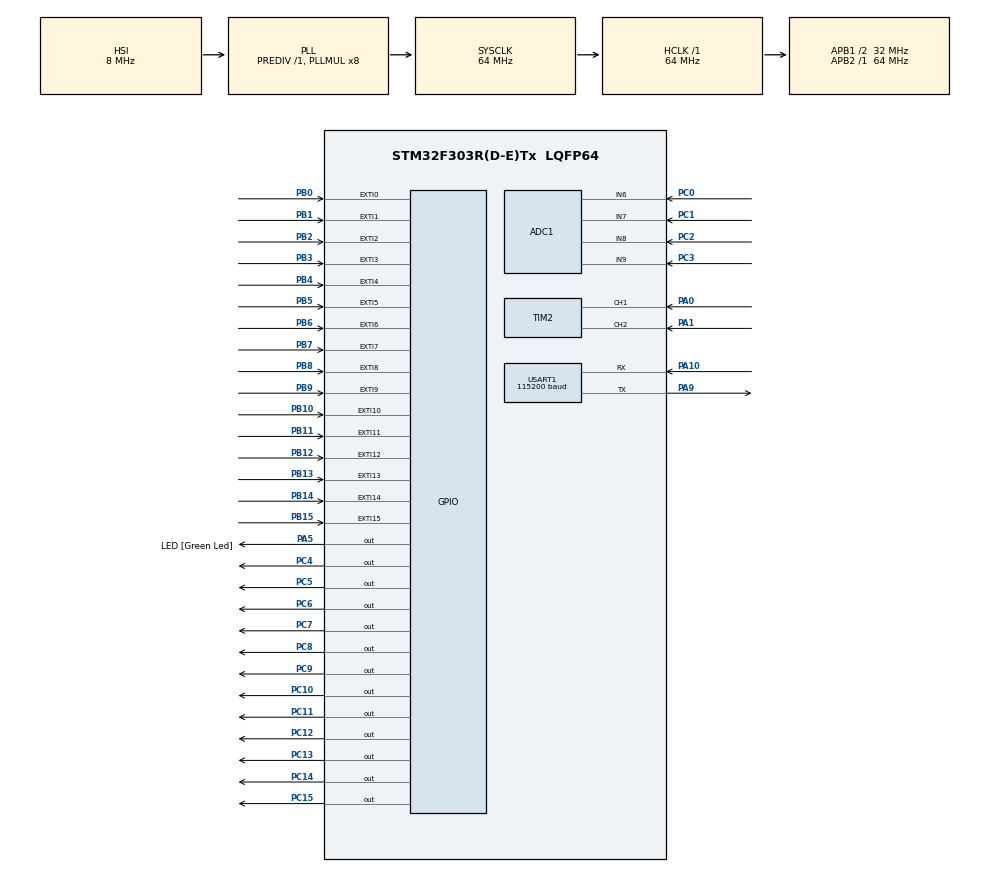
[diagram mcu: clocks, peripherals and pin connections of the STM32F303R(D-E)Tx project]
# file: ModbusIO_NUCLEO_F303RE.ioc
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ADC1.Channel-1\#ChannelRegularConversion=ADC_CHANNEL_6
ADC1.Channel-2\#ChannelRegularConversion=ADC_CHANNEL_7
ADC1.Channel-3\#ChannelRegularConversion=ADC_CHANNEL_8
ADC1.Channel-4\#ChannelRegularConversion=ADC_CHANNEL_9
ADC1.ContinuousConvMode=ENABLE
ADC1.DMAContinuousRequests=ENABLE
ADC1.EOCSelection=ADC_EOC_SEQ_CONV
ADC1.EnableInjectedConversion=DISABLE
ADC1.NbrOfConversion=4
ADC1.NbrOfConversionFlag=1
ADC1.Offset-1\#ChannelRegularConversion=0
ADC1.Offset-2\#ChannelRegularConversion=0
ADC1.Offset-3\#ChannelRegularConversion=0
ADC1.Offset-4\#ChannelRegularConversion=0
ADC1.OffsetNumber-1\#ChannelRegularConversion=ADC_OFFSET_NONE
ADC1.OffsetNumber-2\#ChannelRegularConversion=ADC_OFFSET_NONE
ADC1.OffsetNumber-3\#ChannelRegularConversion=ADC_OFFSET_NONE
ADC1.OffsetNumber-4\#ChannelRegularConversion=ADC_OFFSET_NONE
ADC1.Rank-1\#ChannelRegularConversion=1
ADC1.Rank-2\#ChannelRegularConversion=2
ADC1.Rank-3\#ChannelRegularConversion=3
ADC1.Rank-4\#ChannelRegularConversion=4
ADC1.SamplingTime-1\#ChannelRegularConversion=ADC_SAMPLETIME_61CYCLES_5
ADC1.SamplingTime-2\#ChannelRegularConversion=ADC_SAMPLETIME_61CYCLES_5
ADC1.SamplingTime-3\#ChannelRegularConversion=ADC_SAMPLETIME_61CYCLES_5
ADC1.SamplingTime-4\#ChannelRegularConversion=ADC_SAMPLETIME_61CYCLES_5
ADC1.master=1
Dma.ADC1.0.Direction=DMA_PERIPH_TO_MEMORY
Dma.ADC1.0.Instance=DMA1_Channel1
Dma.ADC1.0.MemDataAlignment=DMA_MDATAALIGN_HALFWORD
Dma.ADC1.0.MemInc=DMA_MINC_ENABLE
Dma.ADC1.0.Mode=DMA_CIRCULAR
Dma.ADC1.0.PeriphDataAlignment=DMA_PDATAALIGN_HALFWORD
Dma.ADC1.0.PeriphInc=DMA_PINC_DISABLE
Dma.ADC1.0.Priority=DMA_PRIORITY_LOW
Dma.Request0=ADC1
Mcu.Family=STM32F3
Mcu.Name=STM32F303R(D-E)Tx
Mcu.Package=LQFP64
NVIC.DMA1_Channel1_IRQn=true\:0\:0\:false\:false\:true\:false\:true\:true
NVIC.EXTI0_IRQn=true\:0\:0\:false\:false\:true\:true\:true\:true
NVIC.EXTI15_10_IRQn=true\:0\:0\:false\:false\:true\:true\:true\:true
NVIC.EXTI1_IRQn=true\:0\:0\:false\:false\:true\:true\:true\:true
NVIC.EXTI2_TSC_IRQn=true\:0\:0\:false\:false\:true\:true\:true\:true
NVIC.EXTI3_IRQn=true\:0\:0\:false\:false\:true\:true\:true\:true
NVIC.EXTI4_IRQn=true\:0\:0\:false\:false\:true\:true\:true\:true
NVIC.EXTI9_5_IRQn=true\:0\:0\:false\:false\:true\:true\:true\:true
NVIC.PriorityGroup=NVIC_PRIORITYGROUP_0
NVIC.USART1_IRQn=true\:0\:0\:false\:false\:true\:true\:true\:true
PA0.Signal=S_TIM2_CH1_ETR
PA1.Signal=S_TIM2_CH2
PA10.Mode=Asynchronous
PA10.Signal=USART1_RX
PA13.GPIO_Label=TMS
PA13.Signal=SYS_JTMS-SWDIO
PA14.GPIO_Label=TCK
PA14.Signal=SYS_JTCK-SWCLK
PA5.GPIO_Label=LED [Green Led]
PA5.GPIO_Mode=GPIO_MODE_OUTPUT_PP
PA5.GPIO_PuPd=GPIO_NOPULL
PA5.GPIO_Speed=GPIO_SPEED_FREQ_LOW
PA5.Signal=GPIO_Output
PA9.Mode=Asynchronous
PA9.Signal=USART1_TX
PB0.GPIO_ModeDefaultEXTI=GPIO_MODE_IT_FALLING
PB0.GPIO_PuPd=GPIO_PULLUP
PB0.Signal=GPXTI0
PB1.GPIO_ModeDefaultEXTI=GPIO_MODE_IT_FALLING
PB1.GPIO_PuPd=GPIO_PULLUP
PB1.Signal=GPXTI1
PB10.GPIO_ModeDefaultEXTI=GPIO_MODE_IT_FALLING
PB10.GPIO_PuPd=GPIO_PULLUP
PB10.Signal=GPXTI10
PB11.GPIO_ModeDefaultEXTI=GPIO_MODE_IT_FALLING
PB11.GPIO_PuPd=GPIO_PULLUP
PB11.Signal=GPXTI11
PB12.GPIO_ModeDefaultEXTI=GPIO_MODE_IT_FALLING
PB12.GPIO_PuPd=GPIO_PULLUP
PB12.Signal=GPXTI12
PB13.GPIO_ModeDefaultEXTI=GPIO_MODE_IT_FALLING
PB13.GPIO_PuPd=GPIO_PULLUP
PB13.Signal=GPXTI13
PB14.GPIO_ModeDefaultEXTI=GPIO_MODE_IT_FALLING
PB14.GPIO_PuPd=GPIO_PULLUP
PB14.Signal=GPXTI14
PB15.GPIO_ModeDefaultEXTI=GPIO_MODE_IT_FALLING
PB15.GPIO_PuPd=GPIO_PULLUP
PB15.Signal=GPXTI15
PB2.GPIO_ModeDefaultEXTI=GPIO_MODE_IT_FALLING
PB2.GPIO_PuPd=GPIO_PULLUP
PB2.Signal=GPXTI2
PB3.GPIO_ModeDefaultEXTI=GPIO_MODE_IT_FALLING
PB3.GPIO_PuPd=GPIO_PULLUP
PB3.Signal=GPXTI3
PB4.GPIO_ModeDefaultEXTI=GPIO_MODE_IT_FALLING
PB4.GPIO_PuPd=GPIO_PULLUP
PB4.Signal=GPXTI4
PB5.GPIO_ModeDefaultEXTI=GPIO_MODE_IT_FALLING
PB5.GPIO_PuPd=GPIO_PULLUP
PB5.Signal=GPXTI5
PB6.GPIO_ModeDefaultEXTI=GPIO_MODE_IT_FALLING
PB6.GPIO_PuPd=GPIO_PULLUP
PB6.Signal=GPXTI6
PB7.GPIO_ModeDefaultEXTI=GPIO_MODE_IT_FALLING
PB7.GPIO_PuPd=GPIO_PULLUP
PB7.Signal=GPXTI7
PB8.GPIO_ModeDefaultEXTI=GPIO_MODE_IT_FALLING
PB8.GPIO_PuPd=GPIO_PULLUP
PB8.Signal=GPXTI8
PB9.GPIO_ModeDefaultEXTI=GPIO_MODE_IT_FALLING
PB9.GPIO_PuPd=GPIO_PULLUP
PB9.Signal=GPXTI9
PC0.Signal=ADCx_IN6
PC1.Signal=ADCx_IN7
PC10.Signal=GPIO_Output
PC11.Signal=GPIO_Output
PC12.Signal=GPIO_Output
PC13.Signal=GPIO_Output
PC14-OSC32_IN.Signal=GPIO_Output
PC15-OSC32_OUT.Signal=GPIO_Output
PC2.Signal=ADCx_IN8
PC3.Signal=ADCx_IN9
PC4.Signal=GPIO_Output
PC5.Signal=GPIO_Output
PC6.Signal=GPIO_Output
PC7.Signal=GPIO_Output
PC8.Signal=GPIO_Output
PC9.Signal=GPIO_Output
PF0-OSC_IN.Signal=RCC_OSC_IN
PF1-OSC_OUT.Signal=RCC_OSC_OUT
ProjectManager.HeapSize=0x200
ProjectManager.StackSize=0x400
ProjectManager.TargetToolchain=STM32CubeIDE
RCC.ADC12PRES=RCC_ADC12PLLCLK_DIV64
RCC.AHBFreq_Value=64000000
RCC.APB1CLKDivider=RCC_HCLK_DIV2
RCC.APB1Freq_Value=32000000
RCC.APB1TimFreq_Value=64000000
RCC.APB2Freq_Value=64000000
RCC.APB2TimFreq_Value=64000000
RCC.CortexFreq_Value=64000000
RCC.HCLKFreq_Value=64000000
RCC.HSE_VALUE=8000000
RCC.HSI_VALUE=8000000
RCC.LSE_VALUE=32768
RCC.PLLM=8
RCC.PLLMUL=RCC_PLL_MUL8
RCC.PLLN=336
RCC.PLLP=RCC_PLLP_DIV4
RCC.PLLQ=7
RCC.RCC_PLLsource_Clock_Source_FROM_HSE=RCC_HSE_PREDIV_DIV2
RCC.SYSCLKFreq_VALUE=64000000
RCC.SYSCLKSourceVirtual=RCC_SYSCLKSOURCE_PLLCLK
RCC.USBFreq_Value=64000000
SH.ADCx_IN6.0=ADC1_IN6,IN6-Single-Ended
SH.ADCx_IN7.0=ADC1_IN7,IN7-Single-Ended
SH.ADCx_IN8.0=ADC1_IN8,IN8-Single-Ended
SH.ADCx_IN9.0=ADC1_IN9,IN9-Single-Ended
SH.S_TIM2_CH1_ETR.0=TIM2_CH1,Encoder_Interface
SH.S_TIM2_CH2.0=TIM2_CH2,Encoder_Interface
USART1.BaudRate=115200
USART1.VirtualMode-Asynchronous=VM_ASYNC
board=NUCLEO-F303RE

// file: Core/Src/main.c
/* USER CODE BEGIN Header */
/**
  ******************************************************************************
  * @file           : main.c
  * @brief          : Main program body
  ******************************************************************************
  * @attention
  *
  * Copyright (c) 2024 STMicroelectronics.
  * All rights reserved.
  *
  * This software is licensed under terms that can be found in the LICENSE file
  * in the root directory of this software component.
  * If no LICENSE file comes with this software, it is provided AS-IS.
  *
  ******************************************************************************
  */
/* USER CODE END Header */
#include "main.h"

ADC_HandleTypeDef hadc1;
DMA_HandleTypeDef hdma_adc1;

TIM_HandleTypeDef htim2;

UART_HandleTypeDef huart1;

void SystemClock_Config(void);
static void MX_GPIO_Init(void);
static void MX_DMA_Init(void);
static void MX_ADC1_Init(void);
static void MX_TIM2_Init(void);
static void MX_USART1_UART_Init(void);

/* USER CODE BEGIN 0 */
void StartPeripherals(void);
void MainLoop(void);
/* USER CODE END 0 */

int main(void)
{

  /* MCU Configuration--------------------------------------------------------*/

  /* Reset of all peripherals, Initializes the Flash interface and the Systick. */
  HAL_Init();

  /* Configure the system clock */
  SystemClock_Config();

  /* Initialize all configured peripherals */
  MX_GPIO_Init();
  MX_DMA_Init();
  MX_ADC1_Init();
  MX_TIM2_Init();
  MX_USART1_UART_Init();
  /* USER CODE BEGIN 2 */
  StartPeripherals();
  /* USER CODE END 2 */

  /* Infinite loop */
  /* USER CODE BEGIN WHILE */
  MainLoop();
    /* USER CODE END WHILE */

}

void SystemClock_Config(void)
{
  RCC_OscInitTypeDef RCC_OscInitStruct = {0};
  RCC_ClkInitTypeDef RCC_ClkInitStruct = {0};
  RCC_PeriphCLKInitTypeDef PeriphClkInit = {0};

  /** Initializes the RCC Oscillators according to the specified parameters
  * in the RCC_OscInitTypeDef structure.
  */
  RCC_OscInitStruct.OscillatorType = RCC_OSCILLATORTYPE_HSI;
  RCC_OscInitStruct.HSIState = RCC_HSI_ON;
  RCC_OscInitStruct.HSICalibrationValue = RCC_HSICALIBRATION_DEFAULT;
  RCC_OscInitStruct.PLL.PLLState = RCC_PLL_ON;
  RCC_OscInitStruct.PLL.PLLSource = RCC_PLLSOURCE_HSI;
  RCC_OscInitStruct.PLL.PLLMUL = RCC_PLL_MUL8;
  RCC_OscInitStruct.PLL.PREDIV = RCC_PREDIV_DIV1;
  if (HAL_RCC_OscConfig(&RCC_OscInitStruct) != HAL_OK)
  {
    Error_Handler();
  }

  /** Initializes the CPU, AHB and APB buses clocks
  */
  RCC_ClkInitStruct.ClockType = RCC_CLOCKTYPE_HCLK|RCC_CLOCKTYPE_SYSCLK
                              |RCC_CLOCKTYPE_PCLK1|RCC_CLOCKTYPE_PCLK2;
  RCC_ClkInitStruct.SYSCLKSource = RCC_SYSCLKSOURCE_PLLCLK;
  RCC_ClkInitStruct.AHBCLKDivider = RCC_SYSCLK_DIV1;
  RCC_ClkInitStruct.APB1CLKDivider = RCC_HCLK_DIV2;
  RCC_ClkInitStruct.APB2CLKDivider = RCC_HCLK_DIV1;

  if (HAL_RCC_ClockConfig(&RCC_ClkInitStruct, FLASH_LATENCY_2) != HAL_OK)
  {
    Error_Handler();
  }
  PeriphClkInit.PeriphClockSelection = RCC_PERIPHCLK_USART1|RCC_PERIPHCLK_ADC12
                              |RCC_PERIPHCLK_TIM2;
  PeriphClkInit.Usart1ClockSelection = RCC_USART1CLKSOURCE_PCLK2;
  PeriphClkInit.Adc12ClockSelection = RCC_ADC12PLLCLK_DIV64;
  PeriphClkInit.Tim2ClockSelection = RCC_TIM2CLK_HCLK;
  if (HAL_RCCEx_PeriphCLKConfig(&PeriphClkInit) != HAL_OK)
  {
    Error_Handler();
  }
}

static void MX_ADC1_Init(void)
{

  ADC_MultiModeTypeDef multimode = {0};
  ADC_ChannelConfTypeDef sConfig = {0};

  /** Common config
  */
  hadc1.Instance = ADC1;
  hadc1.Init.ClockPrescaler = ADC_CLOCK_ASYNC_DIV1;
  hadc1.Init.Resolution = ADC_RESOLUTION_12B;
  hadc1.Init.ScanConvMode = ADC_SCAN_ENABLE;
  hadc1.Init.ContinuousConvMode = ENABLE;
  hadc1.Init.DiscontinuousConvMode = DISABLE;
  hadc1.Init.ExternalTrigConvEdge = ADC_EXTERNALTRIGCONVEDGE_NONE;
  hadc1.Init.ExternalTrigConv = ADC_SOFTWARE_START;
  hadc1.Init.DataAlign = ADC_DATAALIGN_RIGHT;
  hadc1.Init.NbrOfConversion = 4;
  hadc1.Init.DMAContinuousRequests = ENABLE;
  hadc1.Init.EOCSelection = ADC_EOC_SEQ_CONV;
  hadc1.Init.LowPowerAutoWait = DISABLE;
  hadc1.Init.Overrun = ADC_OVR_DATA_OVERWRITTEN;
  if (HAL_ADC_Init(&hadc1) != HAL_OK)
  {
    Error_Handler();
  }

  /** Configure the ADC multi-mode
  */
  multimode.Mode = ADC_MODE_INDEPENDENT;
  if (HAL_ADCEx_MultiModeConfigChannel(&hadc1, &multimode) != HAL_OK)
  {
    Error_Handler();
  }

  /** Configure Regular Channel
  */
  sConfig.Channel = ADC_CHANNEL_6;
  sConfig.Rank = ADC_REGULAR_RANK_1;
  sConfig.SingleDiff = ADC_SINGLE_ENDED;
  sConfig.SamplingTime = ADC_SAMPLETIME_61CYCLES_5;
  sConfig.OffsetNumber = ADC_OFFSET_NONE;
  sConfig.Offset = 0;
  if (HAL_ADC_ConfigChannel(&hadc1, &sConfig) != HAL_OK)
  {
    Error_Handler();
  }

  /** Configure Regular Channel
  */
  sConfig.Channel = ADC_CHANNEL_7;
  sConfig.Rank = ADC_REGULAR_RANK_2;
  if (HAL_ADC_ConfigChannel(&hadc1, &sConfig) != HAL_OK)
  {
    Error_Handler();
  }

  /** Configure Regular Channel
  */
  sConfig.Channel = ADC_CHANNEL_8;
  sConfig.Rank = ADC_REGULAR_RANK_3;
  if (HAL_ADC_ConfigChannel(&hadc1, &sConfig) != HAL_OK)
  {
    Error_Handler();
  }

  /** Configure Regular Channel
  */
  sConfig.Channel = ADC_CHANNEL_9;
  sConfig.Rank = ADC_REGULAR_RANK_4;
  if (HAL_ADC_ConfigChannel(&hadc1, &sConfig) != HAL_OK)
  {
    Error_Handler();
  }

}

static void MX_TIM2_Init(void)
{

  TIM_Encoder_InitTypeDef sConfig = {0};
  TIM_MasterConfigTypeDef sMasterConfig = {0};

  htim2.Instance = TIM2;
  htim2.Init.Prescaler = 0;
  htim2.Init.CounterMode = TIM_COUNTERMODE_UP;
  htim2.Init.Period = 4294967295;
  htim2.Init.ClockDivision = TIM_CLOCKDIVISION_DIV1;
  htim2.Init.AutoReloadPreload = TIM_AUTORELOAD_PRELOAD_DISABLE;
  sConfig.EncoderMode = TIM_ENCODERMODE_TI1;
  sConfig.IC1Polarity = TIM_ICPOLARITY_RISING;
  sConfig.IC1Selection = TIM_ICSELECTION_DIRECTTI;
  sConfig.IC1Prescaler = TIM_ICPSC_DIV1;
  sConfig.IC1Filter = 0;
  sConfig.IC2Polarity = TIM_ICPOLARITY_RISING;
  sConfig.IC2Selection = TIM_ICSELECTION_DIRECTTI;
  sConfig.IC2Prescaler = TIM_ICPSC_DIV1;
  sConfig.IC2Filter = 0;
  if (HAL_TIM_Encoder_Init(&htim2, &sConfig) != HAL_OK)
  {
    Error_Handler();
  }
  sMasterConfig.MasterOutputTrigger = TIM_TRGO_RESET;
  sMasterConfig.MasterSlaveMode = TIM_MASTERSLAVEMODE_DISABLE;
  if (HAL_TIMEx_MasterConfigSynchronization(&htim2, &sMasterConfig) != HAL_OK)
  {
    Error_Handler();
  }

}

static void MX_USART1_UART_Init(void)
{

  huart1.Instance = USART1;
  huart1.Init.BaudRate = 115200;
  huart1.Init.WordLength = UART_WORDLENGTH_8B;
  huart1.Init.StopBits = UART_STOPBITS_1;
  huart1.Init.Parity = UART_PARITY_NONE;
  huart1.Init.Mode = UART_MODE_TX_RX;
  huart1.Init.HwFlowCtl = UART_HWCONTROL_NONE;
  huart1.Init.OverSampling = UART_OVERSAMPLING_16;
  huart1.Init.OneBitSampling = UART_ONE_BIT_SAMPLE_DISABLE;
  huart1.AdvancedInit.AdvFeatureInit = UART_ADVFEATURE_NO_INIT;
  if (HAL_UART_Init(&huart1) != HAL_OK)
  {
    Error_Handler();
  }

}

static void MX_DMA_Init(void)
{

  /* DMA controller clock enable */
  __HAL_RCC_DMA1_CLK_ENABLE();

  /* DMA interrupt init */
  /* DMA1_Channel1_IRQn interrupt configuration */
  HAL_NVIC_SetPriority(DMA1_Channel1_IRQn, 0, 0);
  HAL_NVIC_EnableIRQ(DMA1_Channel1_IRQn);

}

static void MX_GPIO_Init(void)
{
  GPIO_InitTypeDef GPIO_InitStruct = {0};

  /* GPIO Ports Clock Enable */
  __HAL_RCC_GPIOF_CLK_ENABLE();
  __HAL_RCC_GPIOC_CLK_ENABLE();
  __HAL_RCC_GPIOA_CLK_ENABLE();
  __HAL_RCC_GPIOB_CLK_ENABLE();

  /*Configure GPIO pin Output Level */
  HAL_GPIO_WritePin(LED_GPIO_Port, LED_Pin, GPIO_PIN_RESET);

  /*Configure GPIO pin Output Level */
  HAL_GPIO_WritePin(GPIOC, GPIO_PIN_13|GPIO_PIN_14|GPIO_PIN_15|GPIO_PIN_4
                          |GPIO_PIN_5|GPIO_PIN_6|GPIO_PIN_7|GPIO_PIN_8
                          |GPIO_PIN_9|GPIO_PIN_10|GPIO_PIN_11|GPIO_PIN_12, GPIO_PIN_RESET);

  /*Configure GPIO pin : LED_Pin */
  GPIO_InitStruct.Pin = LED_Pin;
  GPIO_InitStruct.Mode = GPIO_MODE_OUTPUT_PP;
  GPIO_InitStruct.Pull = GPIO_NOPULL;
  GPIO_InitStruct.Speed = GPIO_SPEED_FREQ_LOW;
  HAL_GPIO_Init(LED_GPIO_Port, &GPIO_InitStruct);

  /*Configure GPIO pins : PC13 PC14 PC15 PC4
                           PC5 PC6 PC7 PC8
                           PC9 PC10 PC11 PC12 */
  GPIO_InitStruct.Pin = GPIO_PIN_13|GPIO_PIN_14|GPIO_PIN_15|GPIO_PIN_4
                          |GPIO_PIN_5|GPIO_PIN_6|GPIO_PIN_7|GPIO_PIN_8
                          |GPIO_PIN_9|GPIO_PIN_10|GPIO_PIN_11|GPIO_PIN_12;
  GPIO_InitStruct.Mode = GPIO_MODE_OUTPUT_PP;
  GPIO_InitStruct.Pull = GPIO_NOPULL;
  GPIO_InitStruct.Speed = GPIO_SPEED_FREQ_LOW;
  HAL_GPIO_Init(GPIOC, &GPIO_InitStruct);

  /*Configure GPIO pins : PB0 PB1 PB2 PB10
                           PB11 PB12 PB13 PB14
                           PB15 PB3 PB4 PB5
                           PB6 PB7 PB8 PB9 */
  GPIO_InitStruct.Pin = GPIO_PIN_0|GPIO_PIN_1|GPIO_PIN_2|GPIO_PIN_10
                          |GPIO_PIN_11|GPIO_PIN_12|GPIO_PIN_13|GPIO_PIN_14
                          |GPIO_PIN_15|GPIO_PIN_3|GPIO_PIN_4|GPIO_PIN_5
                          |GPIO_PIN_6|GPIO_PIN_7|GPIO_PIN_8|GPIO_PIN_9;
  GPIO_InitStruct.Mode = GPIO_MODE_IT_FALLING;
  GPIO_InitStruct.Pull = GPIO_PULLUP;
  HAL_GPIO_Init(GPIOB, &GPIO_InitStruct);

  /* EXTI interrupt init*/
  HAL_NVIC_SetPriority(EXTI0_IRQn, 0, 0);
  HAL_NVIC_EnableIRQ(EXTI0_IRQn);

  HAL_NVIC_SetPriority(EXTI1_IRQn, 0, 0);
  HAL_NVIC_EnableIRQ(EXTI1_IRQn);

  HAL_NVIC_SetPriority(EXTI2_TSC_IRQn, 0, 0);
  HAL_NVIC_EnableIRQ(EXTI2_TSC_IRQn);

  HAL_NVIC_SetPriority(EXTI3_IRQn, 0, 0);
  HAL_NVIC_EnableIRQ(EXTI3_IRQn);

  HAL_NVIC_SetPriority(EXTI4_IRQn, 0, 0);
  HAL_NVIC_EnableIRQ(EXTI4_IRQn);

  HAL_NVIC_SetPriority(EXTI9_5_IRQn, 0, 0);
  HAL_NVIC_EnableIRQ(EXTI9_5_IRQn);

  HAL_NVIC_SetPriority(EXTI15_10_IRQn, 0, 0);
  HAL_NVIC_EnableIRQ(EXTI15_10_IRQn);

}

void Error_Handler(void)
{
  __disable_irq();
  while (1)
  {
  }
}
